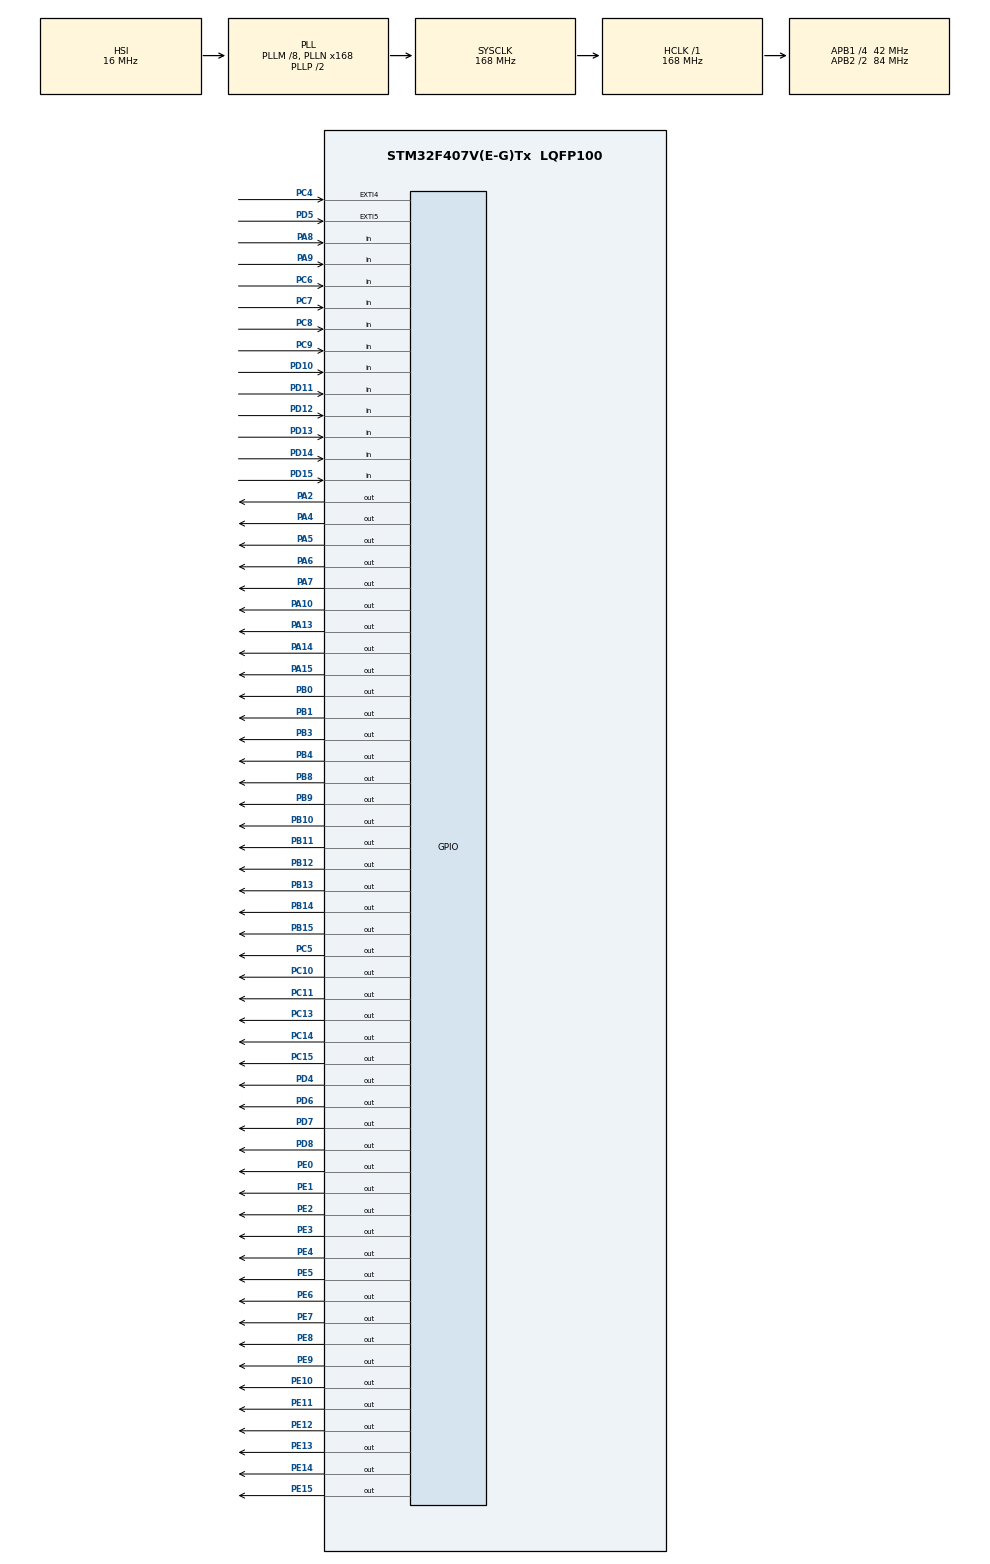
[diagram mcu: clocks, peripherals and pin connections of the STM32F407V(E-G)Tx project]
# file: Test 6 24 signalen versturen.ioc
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Mcu.Family=STM32F4
Mcu.Name=STM32F407V(E-G)Tx
Mcu.Package=LQFP100
NVIC.PriorityGroup=NVIC_PRIORITYGROUP_0
PA0-WKUP.Signal=UART4_TX
PA1.Signal=UART4_RX
PA10.Signal=GPIO_Output
PA13.Signal=GPIO_Output
PA14.Signal=GPIO_Output
PA15.Signal=GPIO_Output
PA2.Signal=GPIO_Output
PA4.Signal=GPIO_Output
PA5.Signal=GPIO_Output
PA6.Signal=GPIO_Output
PA7.Signal=GPIO_Output
PA8.Signal=GPIO_Input
PA9.Signal=GPIO_Input
PB0.Signal=GPIO_Output
PB1.Signal=GPIO_Output
PB10.Signal=GPIO_Output
PB11.Signal=GPIO_Output
PB12.Signal=GPIO_Output
PB13.Signal=GPIO_Output
PB14.Signal=GPIO_Output
PB15.Signal=GPIO_Output
PB3.Signal=GPIO_Output
PB4.Signal=GPIO_Output
PB6.Signal=I2C1_SCL
PB7.Signal=I2C1_SDA
PB8.Signal=GPIO_Output
PB9.Signal=GPIO_Output
PC10.Signal=GPIO_Output
PC11.Signal=GPIO_Output
PC12.Signal=UART5_TX
PC13-ANTI_TAMP.Signal=GPIO_Output
PC14-OSC32_IN.Signal=GPIO_Output
PC15-OSC32_OUT.Signal=GPIO_Output
PC4.Signal=GPXTI4
PC5.Signal=GPIO_Output
PC6.Signal=GPIO_Input
PC7.Signal=GPIO_Input
PC8.Signal=GPIO_Input
PC9.Signal=GPIO_Input
PD10.Signal=GPIO_Input
PD11.Signal=GPIO_Input
PD12.Signal=GPIO_Input
PD13.Signal=GPIO_Input
PD14.Signal=GPIO_Input
PD15.Signal=GPIO_Input
PD2.Signal=UART5_RX
PD4.Signal=GPIO_Output
PD5.Signal=GPXTI5
PD6.Signal=GPIO_Output
PD7.Signal=GPIO_Output
PD8.Signal=GPIO_Output
PE0.Signal=GPIO_Output
PE1.Signal=GPIO_Output
PE10.Signal=GPIO_Output
PE11.Signal=GPIO_Output
PE12.Signal=GPIO_Output
PE13.Signal=GPIO_Output
PE14.Signal=GPIO_Output
PE15.Signal=GPIO_Output
PE2.Signal=GPIO_Output
PE3.Signal=GPIO_Output
PE4.Signal=GPIO_Output
PE5.Signal=GPIO_Output
PE6.Signal=GPIO_Output
PE7.Signal=GPIO_Output
PE8.Signal=GPIO_Output
PE9.Signal=GPIO_Output
ProjectManager.HeapSize=0x200
ProjectManager.StackSize=0x400
ProjectManager.TargetToolchain=STM32CubeIDE
RCC.48MHZClocksFreq_Value=48000000
RCC.AHBFreq_Value=168000000
RCC.APB1CLKDivider=RCC_HCLK_DIV4
RCC.APB1Freq_Value=42000000
RCC.APB1TimFreq_Value=84000000
RCC.APB2CLKDivider=RCC_HCLK_DIV2
RCC.APB2Freq_Value=84000000
RCC.APB2TimFreq_Value=168000000
RCC.CortexFreq_Value=168000000
RCC.HCLKFreq_Value=168000000
RCC.HSE_VALUE=8000000
RCC.HSI_VALUE=16000000
RCC.PLLM=8
RCC.PLLN=168
RCC.PLLQ=7
RCC.SYSCLKFreq_VALUE=168000000
RCC.SYSCLKSource=RCC_SYSCLKSOURCE_PLLCLK
RCC.VCOOutputFreq_Value=336000000
board=STM32F407G-DISC1

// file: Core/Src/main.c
/* USER CODE BEGIN Header */
/**
  ******************************************************************************
  * @file           : main.c
  * @brief          : Main program body
  ******************************************************************************
  * @attention
  *
  * Copyright (c) 2024 STMicroelectronics.
  * All rights reserved.
  *
  * This software is licensed under terms that can be found in the LICENSE file
  * in the root directory of this software component.
  * If no LICENSE file comes with this software, it is provided AS-IS.
  *
  ******************************************************************************
  */
/* USER CODE END Header */
#include "main.h"

void SystemClock_Config(void);
static void MX_GPIO_Init(void);

int main(void)
{

  /* MCU Configuration--------------------------------------------------------*/

  /* Reset of all peripherals, Initializes the Flash interface and the Systick. */
  HAL_Init();

  /* Configure the system clock */
  SystemClock_Config();

  /* Initialize all configured peripherals */
  MX_GPIO_Init();
  /* USER CODE BEGIN 2 */
  HAL_GPIO_WritePin(GPIOE,GPIO_PIN_6 | GPIO_PIN_4 | GPIO_PIN_2 | GPIO_PIN_0 | GPIO_PIN_11| GPIO_PIN_13| GPIO_PIN_15 | GPIO_PIN_7 | GPIO_PIN_9, GPIO_PIN_SET);
  HAL_GPIO_WritePin(GPIOC,GPIO_PIN_10 | GPIO_PIN_5 | GPIO_PIN_14, GPIO_PIN_SET);
  HAL_GPIO_WritePin(GPIOA,GPIO_PIN_14 | GPIO_PIN_10 | GPIO_PIN_5| GPIO_PIN_7, GPIO_PIN_SET);
  HAL_GPIO_WritePin(GPIOB,GPIO_PIN_8 | GPIO_PIN_4 | GPIO_PIN_1 | GPIO_PIN_11 | GPIO_PIN_13| GPIO_PIN_15, GPIO_PIN_SET);
  HAL_GPIO_WritePin(GPIOD,GPIO_PIN_7 | GPIO_PIN_5, GPIO_PIN_SET);
  /* USER CODE END 2 */

  /* Infinite loop */
  while (1)
  {

  }
}

void SystemClock_Config(void)
{
  RCC_OscInitTypeDef RCC_OscInitStruct = {0};
  RCC_ClkInitTypeDef RCC_ClkInitStruct = {0};

  /** Configure the main internal regulator output voltage
  */
  __HAL_RCC_PWR_CLK_ENABLE();
  __HAL_PWR_VOLTAGESCALING_CONFIG(PWR_REGULATOR_VOLTAGE_SCALE1);

  /** Initializes the RCC Oscillators according to the specified parameters
  * in the RCC_OscInitTypeDef structure.
  */
  RCC_OscInitStruct.OscillatorType = RCC_OSCILLATORTYPE_HSI;
  RCC_OscInitStruct.HSIState = RCC_HSI_ON;
  RCC_OscInitStruct.HSICalibrationValue = RCC_HSICALIBRATION_DEFAULT;
  RCC_OscInitStruct.PLL.PLLState = RCC_PLL_ON;
  RCC_OscInitStruct.PLL.PLLSource = RCC_PLLSOURCE_HSI;
  RCC_OscInitStruct.PLL.PLLM = 8;
  RCC_OscInitStruct.PLL.PLLN = 168;
  RCC_OscInitStruct.PLL.PLLP = RCC_PLLP_DIV2;
  RCC_OscInitStruct.PLL.PLLQ = 7;
  if (HAL_RCC_OscConfig(&RCC_OscInitStruct) != HAL_OK)
  {
    Error_Handler();
  }

  /** Initializes the CPU, AHB and APB buses clocks
  */
  RCC_ClkInitStruct.ClockType = RCC_CLOCKTYPE_HCLK|RCC_CLOCKTYPE_SYSCLK
                              |RCC_CLOCKTYPE_PCLK1|RCC_CLOCKTYPE_PCLK2;
  RCC_ClkInitStruct.SYSCLKSource = RCC_SYSCLKSOURCE_PLLCLK;
  RCC_ClkInitStruct.AHBCLKDivider = RCC_SYSCLK_DIV1;
  RCC_ClkInitStruct.APB1CLKDivider = RCC_HCLK_DIV4;
  RCC_ClkInitStruct.APB2CLKDivider = RCC_HCLK_DIV2;

  if (HAL_RCC_ClockConfig(&RCC_ClkInitStruct, FLASH_LATENCY_5) != HAL_OK)
  {
    Error_Handler();
  }
}

static void MX_GPIO_Init(void)
{
  GPIO_InitTypeDef GPIO_InitStruct = {0};

  /* GPIO Ports Clock Enable */
  __HAL_RCC_GPIOE_CLK_ENABLE();
  __HAL_RCC_GPIOC_CLK_ENABLE();
  __HAL_RCC_GPIOA_CLK_ENABLE();
  __HAL_RCC_GPIOB_CLK_ENABLE();
  __HAL_RCC_GPIOD_CLK_ENABLE();

  /*Configure GPIO pin Output Level */
  HAL_GPIO_WritePin(GPIOE, GPIO_PIN_2|GPIO_PIN_3|GPIO_PIN_4|GPIO_PIN_5
                          |GPIO_PIN_6|GPIO_PIN_7|GPIO_PIN_8|GPIO_PIN_9
                          |GPIO_PIN_10|GPIO_PIN_11|GPIO_PIN_12|GPIO_PIN_13
                          |GPIO_PIN_14|GPIO_PIN_15|GPIO_PIN_0|GPIO_PIN_1, GPIO_PIN_RESET);

  /*Configure GPIO pin Output Level */
  HAL_GPIO_WritePin(GPIOC, GPIO_PIN_13|GPIO_PIN_14|GPIO_PIN_15|GPIO_PIN_5
                          |GPIO_PIN_10|GPIO_PIN_11, GPIO_PIN_RESET);

  /*Configure GPIO pin Output Level */
  HAL_GPIO_WritePin(GPIOA, GPIO_PIN_2|GPIO_PIN_4|GPIO_PIN_5|GPIO_PIN_6
                          |GPIO_PIN_7|GPIO_PIN_10|GPIO_PIN_13|GPIO_PIN_14
                          |GPIO_PIN_15, GPIO_PIN_RESET);

  /*Configure GPIO pin Output Level */
  HAL_GPIO_WritePin(GPIOB, GPIO_PIN_0|GPIO_PIN_1|GPIO_PIN_10|GPIO_PIN_11
                          |GPIO_PIN_12|GPIO_PIN_13|GPIO_PIN_14|GPIO_PIN_15
                          |GPIO_PIN_3|GPIO_PIN_4|GPIO_PIN_8|GPIO_PIN_9, GPIO_PIN_RESET);

  /*Configure GPIO pin Output Level */
  HAL_GPIO_WritePin(GPIOD, GPIO_PIN_8|GPIO_PIN_4|GPIO_PIN_6|GPIO_PIN_7, GPIO_PIN_RESET);

  /*Configure GPIO pins : PE2 PE3 PE4 PE5
                           PE6 PE7 PE8 PE9
                           PE10 PE11 PE12 PE13
                           PE14 PE15 PE0 PE1 */
  GPIO_InitStruct.Pin = GPIO_PIN_2|GPIO_PIN_3|GPIO_PIN_4|GPIO_PIN_5
                          |GPIO_PIN_6|GPIO_PIN_7|GPIO_PIN_8|GPIO_PIN_9
                          |GPIO_PIN_10|GPIO_PIN_11|GPIO_PIN_12|GPIO_PIN_13
                          |GPIO_PIN_14|GPIO_PIN_15|GPIO_PIN_0|GPIO_PIN_1;
  GPIO_InitStruct.Mode = GPIO_MODE_OUTPUT_PP;
  GPIO_InitStruct.Pull = GPIO_NOPULL;
  GPIO_InitStruct.Speed = GPIO_SPEED_FREQ_LOW;
  HAL_GPIO_Init(GPIOE, &GPIO_InitStruct);

  /*Configure GPIO pins : PC13 PC14 PC15 PC5
                           PC10 PC11 */
  GPIO_InitStruct.Pin = GPIO_PIN_13|GPIO_PIN_14|GPIO_PIN_15|GPIO_PIN_5
                          |GPIO_PIN_10|GPIO_PIN_11;
  GPIO_InitStruct.Mode = GPIO_MODE_OUTPUT_PP;
  GPIO_InitStruct.Pull = GPIO_NOPULL;
  GPIO_InitStruct.Speed = GPIO_SPEED_FREQ_LOW;
  HAL_GPIO_Init(GPIOC, &GPIO_InitStruct);

  /*Configure GPIO pins : PA0 PA1 */
  GPIO_InitStruct.Pin = GPIO_PIN_0|GPIO_PIN_1;
  GPIO_InitStruct.Mode = GPIO_MODE_AF_PP;
  GPIO_InitStruct.Pull = GPIO_NOPULL;
  GPIO_InitStruct.Speed = GPIO_SPEED_FREQ_VERY_HIGH;
  GPIO_InitStruct.Alternate = GPIO_AF8_UART4;
  HAL_GPIO_Init(GPIOA, &GPIO_InitStruct);

  /*Configure GPIO pins : PA2 PA4 PA5 PA6
                           PA7 PA10 PA13 PA14
                           PA15 */
  GPIO_InitStruct.Pin = GPIO_PIN_2|GPIO_PIN_4|GPIO_PIN_5|GPIO_PIN_6
                          |GPIO_PIN_7|GPIO_PIN_10|GPIO_PIN_13|GPIO_PIN_14
                          |GPIO_PIN_15;
  GPIO_InitStruct.Mode = GPIO_MODE_OUTPUT_PP;
  GPIO_InitStruct.Pull = GPIO_NOPULL;
  GPIO_InitStruct.Speed = GPIO_SPEED_FREQ_LOW;
  HAL_GPIO_Init(GPIOA, &GPIO_InitStruct);

  /*Configure GPIO pin : PC4 */
  GPIO_InitStruct.Pin = GPIO_PIN_4;
  GPIO_InitStruct.Mode = GPIO_MODE_IT_RISING;
  GPIO_InitStruct.Pull = GPIO_NOPULL;
  HAL_GPIO_Init(GPIOC, &GPIO_InitStruct);

  /*Configure GPIO pins : PB0 PB1 PB10 PB11
                           PB12 PB13 PB14 PB15
                           PB3 PB4 PB8 PB9 */
  GPIO_InitStruct.Pin = GPIO_PIN_0|GPIO_PIN_1|GPIO_PIN_10|GPIO_PIN_11
                          |GPIO_PIN_12|GPIO_PIN_13|GPIO_PIN_14|GPIO_PIN_15
                          |GPIO_PIN_3|GPIO_PIN_4|GPIO_PIN_8|GPIO_PIN_9;
  GPIO_InitStruct.Mode = GPIO_MODE_OUTPUT_PP;
  GPIO_InitStruct.Pull = GPIO_NOPULL;
  GPIO_InitStruct.Speed = GPIO_SPEED_FREQ_LOW;
  HAL_GPIO_Init(GPIOB, &GPIO_InitStruct);

  /*Configure GPIO pins : PD8 PD4 PD6 PD7 */
  GPIO_InitStruct.Pin = GPIO_PIN_8|GPIO_PIN_4|GPIO_PIN_6|GPIO_PIN_7;
  GPIO_InitStruct.Mode = GPIO_MODE_OUTPUT_PP;
  GPIO_InitStruct.Pull = GPIO_NOPULL;
  GPIO_InitStruct.Speed = GPIO_SPEED_FREQ_LOW;
  HAL_GPIO_Init(GPIOD, &GPIO_InitStruct);

  /*Configure GPIO pins : PD10 PD11 PD12 PD13
                           PD14 PD15 */
  GPIO_InitStruct.Pin = GPIO_PIN_10|GPIO_PIN_11|GPIO_PIN_12|GPIO_PIN_13
                          |GPIO_PIN_14|GPIO_PIN_15;
  GPIO_InitStruct.Mode = GPIO_MODE_INPUT;
  GPIO_InitStruct.Pull = GPIO_NOPULL;
  HAL_GPIO_Init(GPIOD, &GPIO_InitStruct);

  /*Configure GPIO pins : PC6 PC7 PC8 PC9 */
  GPIO_InitStruct.Pin = GPIO_PIN_6|GPIO_PIN_7|GPIO_PIN_8|GPIO_PIN_9;
  GPIO_InitStruct.Mode = GPIO_MODE_INPUT;
  GPIO_InitStruct.Pull = GPIO_NOPULL;
  HAL_GPIO_Init(GPIOC, &GPIO_InitStruct);

  /*Configure GPIO pins : PA8 PA9 */
  GPIO_InitStruct.Pin = GPIO_PIN_8|GPIO_PIN_9;
  GPIO_InitStruct.Mode = GPIO_MODE_INPUT;
  GPIO_InitStruct.Pull = GPIO_NOPULL;
  HAL_GPIO_Init(GPIOA, &GPIO_InitStruct);

  /*Configure GPIO pin : PC12 */
  GPIO_InitStruct.Pin = GPIO_PIN_12;
  GPIO_InitStruct.Mode = GPIO_MODE_AF_PP;
  GPIO_InitStruct.Pull = GPIO_NOPULL;
  GPIO_InitStruct.Speed = GPIO_SPEED_FREQ_VERY_HIGH;
  GPIO_InitStruct.Alternate = GPIO_AF8_UART5;
  HAL_GPIO_Init(GPIOC, &GPIO_InitStruct);

  /*Configure GPIO pin : PD2 */
  GPIO_InitStruct.Pin = GPIO_PIN_2;
  GPIO_InitStruct.Mode = GPIO_MODE_AF_PP;
  GPIO_InitStruct.Pull = GPIO_NOPULL;
  GPIO_InitStruct.Speed = GPIO_SPEED_FREQ_VERY_HIGH;
  GPIO_InitStruct.Alternate = GPIO_AF8_UART5;
  HAL_GPIO_Init(GPIOD, &GPIO_InitStruct);

  /*Configure GPIO pin : PD5 */
  GPIO_InitStruct.Pin = GPIO_PIN_5;
  GPIO_InitStruct.Mode = GPIO_MODE_IT_RISING;
  GPIO_InitStruct.Pull = GPIO_NOPULL;
  HAL_GPIO_Init(GPIOD, &GPIO_InitStruct);

  /*Configure GPIO pins : PB6 PB7 */
  GPIO_InitStruct.Pin = GPIO_PIN_6|GPIO_PIN_7;
  GPIO_InitStruct.Mode = GPIO_MODE_AF_OD;
  GPIO_InitStruct.Pull = GPIO_NOPULL;
  GPIO_InitStruct.Speed = GPIO_SPEED_FREQ_VERY_HIGH;
  GPIO_InitStruct.Alternate = GPIO_AF4_I2C1;
  HAL_GPIO_Init(GPIOB, &GPIO_InitStruct);

}

void Error_Handler(void)
{
  __disable_irq();
  while (1)
  {
  }
}
